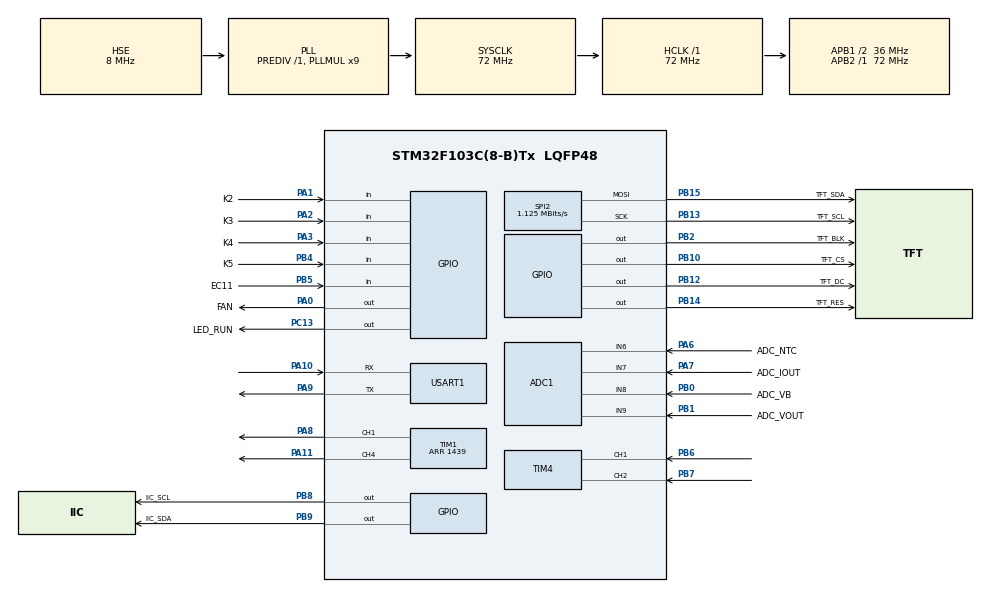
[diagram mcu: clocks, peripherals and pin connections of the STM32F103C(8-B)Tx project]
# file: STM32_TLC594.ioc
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ADC1.Channel-2\#ChannelRegularConversion=ADC_CHANNEL_6
ADC1.Channel-3\#ChannelRegularConversion=ADC_CHANNEL_7
ADC1.Channel-4\#ChannelRegularConversion=ADC_CHANNEL_8
ADC1.Channel-5\#ChannelRegularConversion=ADC_CHANNEL_9
ADC1.ContinuousConvMode=ENABLE
ADC1.EnableInjectedConversion=DISABLE
ADC1.EnableRegularConversion=ENABLE
ADC1.NbrOfConversion=4
ADC1.NbrOfConversionFlag=1
ADC1.Rank-2\#ChannelRegularConversion=1
ADC1.Rank-3\#ChannelRegularConversion=2
ADC1.Rank-4\#ChannelRegularConversion=3
ADC1.Rank-5\#ChannelRegularConversion=4
ADC1.SamplingTime-2\#ChannelRegularConversion=ADC_SAMPLETIME_13CYCLES_5
ADC1.SamplingTime-3\#ChannelRegularConversion=ADC_SAMPLETIME_13CYCLES_5
ADC1.SamplingTime-4\#ChannelRegularConversion=ADC_SAMPLETIME_13CYCLES_5
ADC1.SamplingTime-5\#ChannelRegularConversion=ADC_SAMPLETIME_13CYCLES_5
ADC1.master=1
Dma.ADC1.0.Direction=DMA_PERIPH_TO_MEMORY
Dma.ADC1.0.Instance=DMA1_Channel1
Dma.ADC1.0.MemDataAlignment=DMA_MDATAALIGN_HALFWORD
Dma.ADC1.0.MemInc=DMA_MINC_ENABLE
Dma.ADC1.0.Mode=DMA_CIRCULAR
Dma.ADC1.0.PeriphDataAlignment=DMA_PDATAALIGN_HALFWORD
Dma.ADC1.0.PeriphInc=DMA_PINC_DISABLE
Dma.ADC1.0.Priority=DMA_PRIORITY_HIGH
Dma.Request0=ADC1
Mcu.Family=STM32F1
Mcu.Name=STM32F103C(8-B)Tx
Mcu.Package=LQFP48
NVIC.DMA1_Channel1_IRQn=true\:0\:0\:false\:false\:true\:false\:true\:true
NVIC.PriorityGroup=NVIC_PRIORITYGROUP_4
NVIC.TIM2_IRQn=true\:0\:0\:false\:false\:true\:true\:true\:true
NVIC.TIM4_IRQn=true\:0\:0\:false\:false\:true\:true\:true\:true
NVIC.USART1_IRQn=true\:0\:0\:false\:false\:true\:true\:true\:true
PA0-WKUP.GPIO_Label=FAN
PA0-WKUP.PinState=GPIO_PIN_RESET
PA0-WKUP.Signal=GPIO_Output
PA1.GPIO_Label=K2
PA1.GPIO_PuPd=GPIO_PULLUP
PA1.Signal=GPIO_Input
PA10.Mode=Asynchronous
PA10.Signal=USART1_RX
PA11.Signal=S_TIM1_CH4
PA13.Mode=Serial_Wire
PA13.Signal=SYS_JTMS-SWDIO
PA14.Mode=Serial_Wire
PA14.Signal=SYS_JTCK-SWCLK
PA2.GPIO_Label=K3
PA2.GPIO_PuPd=GPIO_PULLUP
PA2.Signal=GPIO_Input
PA3.GPIO_Label=K4
PA3.GPIO_PuPd=GPIO_PULLUP
PA3.Signal=GPIO_Input
PA6.GPIO_Label=ADC_NTC
PA6.Signal=ADCx_IN6
PA7.GPIO_Label=ADC_IOUT
PA7.Signal=ADCx_IN7
PA8.Signal=S_TIM1_CH1
PA9.Mode=Asynchronous
PA9.Signal=USART1_TX
PB0.GPIO_Label=ADC_VB
PB0.Signal=ADCx_IN8
PB1.GPIO_Label=ADC_VOUT
PB1.Signal=ADCx_IN9
PB10.GPIO_Label=TFT_CS
PB10.PinState=GPIO_PIN_SET
PB10.Signal=GPIO_Output
PB12.GPIO_Label=TFT_DC
PB12.PinState=GPIO_PIN_SET
PB12.Signal=GPIO_Output
PB13.GPIO_Label=TFT_SCL
PB13.Mode=TX_Only_Simplex_Unidirect_Master
PB13.Signal=SPI2_SCK
PB14.GPIO_Label=TFT_RES
PB14.PinState=GPIO_PIN_SET
PB14.Signal=GPIO_Output
PB15.GPIO_Label=TFT_SDA
PB15.Mode=TX_Only_Simplex_Unidirect_Master
PB15.Signal=SPI2_MOSI
PB2.GPIO_Label=TFT_BLK
PB2.Signal=GPIO_Output
PB4.GPIO_Label=K5
PB4.GPIO_PuPd=GPIO_PULLUP
PB4.Signal=GPIO_Input
PB5.GPIO_Label=EC11
PB5.GPIO_PuPd=GPIO_PULLUP
PB5.Signal=GPIO_Input
PB6.GPIO_PuPd=GPIO_PULLUP
PB6.Signal=S_TIM4_CH1
PB7.GPIO_PuPd=GPIO_PULLUP
PB7.Signal=S_TIM4_CH2
PB8.GPIO_Label=IIC_SCL
PB8.GPIO_Speed=GPIO_SPEED_FREQ_HIGH
PB8.Signal=GPIO_Output
PB9.GPIO_Label=IIC_SDA
PB9.GPIO_Speed=GPIO_SPEED_FREQ_HIGH
PB9.Signal=GPIO_Output
PC13-TAMPER-RTC.GPIO_Label=LED_RUN
PC13-TAMPER-RTC.Signal=GPIO_Output
PD0-OSC_IN.Mode=HSE-External-Oscillator
PD0-OSC_IN.Signal=RCC_OSC_IN
PD1-OSC_OUT.Mode=HSE-External-Oscillator
PD1-OSC_OUT.Signal=RCC_OSC_OUT
ProjectManager.HeapSize=0x200
ProjectManager.StackSize=0x400
ProjectManager.TargetToolchain=CMake
RCC.ADCPresc=RCC_ADCPCLK2_DIV6
RCC.AHBFreq_Value=72000000
RCC.APB1CLKDivider=RCC_HCLK_DIV2
RCC.APB1Freq_Value=36000000
RCC.APB1TimFreq_Value=72000000
RCC.APB2Freq_Value=72000000
RCC.APB2TimFreq_Value=72000000
RCC.HCLKFreq_Value=72000000
RCC.PLLMUL=RCC_PLL_MUL9
RCC.PLLSourceVirtual=RCC_PLLSOURCE_HSE
RCC.SYSCLKFreq_VALUE=72000000
RCC.SYSCLKSource=RCC_SYSCLKSOURCE_PLLCLK
RCC.USBFreq_Value=72000000
SH.ADCx_IN6.0=ADC1_IN6,IN6
SH.ADCx_IN7.0=ADC1_IN7,IN7
SH.ADCx_IN8.0=ADC1_IN8,IN8
SH.ADCx_IN9.0=ADC1_IN9,IN9
SH.S_TIM1_CH1.0=TIM1_CH1,PWM Generation1 CH1
SH.S_TIM1_CH4.0=TIM1_CH4,PWM Generation4 CH4
SH.S_TIM4_CH1.0=TIM4_CH1,Encoder_Interface
SH.S_TIM4_CH2.0=TIM4_CH2,Encoder_Interface
SPI2.BaudRatePrescaler=SPI_BAUDRATEPRESCALER_32
SPI2.CLKPhase=SPI_PHASE_2EDGE
SPI2.CLKPolarity=SPI_POLARITY_HIGH
SPI2.CalculateBaudRate=1.125 MBits/s
SPI2.Direction=SPI_DIRECTION_2LINES
SPI2.Mode=SPI_MODE_MASTER
SPI2.VirtualType=VM_MASTER
TIM1.AutoReloadPreload=TIM_AUTORELOAD_PRELOAD_ENABLE
TIM1.Channel-PWM\ Generation1\ CH1=TIM_CHANNEL_1
TIM1.Channel-PWM\ Generation4\ CH4=TIM_CHANNEL_4
TIM1.Period=1439
TIM1.Pulse-PWM\ Generation1\ CH1=720
TIM1.Pulse-PWM\ Generation4\ CH4=720
TIM2.AutoReloadPreload=TIM_AUTORELOAD_PRELOAD_ENABLE
TIM2.Period=4999
TIM2.Prescaler=71
TIM3.Period=89
TIM4.IC1Filter=6
TIM4.IC2Filter=6
USART1.VirtualMode=VM_ASYNC
VP_TIM2_VS_ClockSourceINT.Mode=Internal
VP_TIM3_VS_ClockSourceINT.Mode=Internal
board=custom

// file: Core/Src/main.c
/* USER CODE BEGIN Header */
/**
  ******************************************************************************
  * @file           : main.c
  * @brief          : Main program body
  ******************************************************************************
  * @attention
  *
  * Copyright (c) 2025 STMicroelectronics.
  * All rights reserved.
  *
  * This software is licensed under terms that can be found in the LICENSE file
  * in the root directory of this software component.
  * If no LICENSE file comes with this software, it is provided AS-IS.
  *
  ******************************************************************************
  */
/* USER CODE END Header */
#include "main.h"
#include "adc.h"
#include "dma.h"
#include "spi.h"
#include "tim.h"
#include "usart.h"
#include "gpio.h"

/* USER CODE BEGIN Includes */
#include "MyApplication.h"

/* USER CODE END Includes */

void SystemClock_Config(void);

int main(void)
{

  /* USER CODE BEGIN 1 */
  //uint8_t Key_num;
  Function_SET.OutPutState = CV_State;
  /* USER CODE END 1 */

  /* MCU Configuration--------------------------------------------------------*/

  /* Reset of all peripherals, Initializes the Flash interface and the Systick. */
  HAL_Init();

  /* Configure the system clock */
  SystemClock_Config();

  /* Initialize all configured peripherals */
  MX_GPIO_Init();
  MX_DMA_Init();
  MX_ADC1_Init();
  MX_TIM1_Init();
  MX_TIM2_Init();
  MX_TIM3_Init();
  MX_TIM4_Init();
  MX_USART1_UART_Init();
  MX_SPI2_Init();
  /* USER CODE BEGIN 2 */
  MyInit.Peripheral_Set();

  /* USER CODE END 2 */

  /* Infinite loop */
  while (1)
  {

    /* USER CODE BEGIN 3 */
    System.Run();
  }
  /* USER CODE END 3 */
}

void SystemClock_Config(void)
{
  RCC_OscInitTypeDef RCC_OscInitStruct = {0};
  RCC_ClkInitTypeDef RCC_ClkInitStruct = {0};
  RCC_PeriphCLKInitTypeDef PeriphClkInit = {0};

  /** Initializes the RCC Oscillators according to the specified parameters
  * in the RCC_OscInitTypeDef structure.
  */
  RCC_OscInitStruct.OscillatorType = RCC_OSCILLATORTYPE_HSE;
  RCC_OscInitStruct.HSEState = RCC_HSE_ON;
  RCC_OscInitStruct.HSEPredivValue = RCC_HSE_PREDIV_DIV1;
  RCC_OscInitStruct.HSIState = RCC_HSI_ON;
  RCC_OscInitStruct.PLL.PLLState = RCC_PLL_ON;
  RCC_OscInitStruct.PLL.PLLSource = RCC_PLLSOURCE_HSE;
  RCC_OscInitStruct.PLL.PLLMUL = RCC_PLL_MUL9;
  if (HAL_RCC_OscConfig(&RCC_OscInitStruct) != HAL_OK)
  {
    Error_Handler();
  }

  /** Initializes the CPU, AHB and APB buses clocks
  */
  RCC_ClkInitStruct.ClockType = RCC_CLOCKTYPE_HCLK|RCC_CLOCKTYPE_SYSCLK
                              |RCC_CLOCKTYPE_PCLK1|RCC_CLOCKTYPE_PCLK2;
  RCC_ClkInitStruct.SYSCLKSource = RCC_SYSCLKSOURCE_PLLCLK;
  RCC_ClkInitStruct.AHBCLKDivider = RCC_SYSCLK_DIV1;
  RCC_ClkInitStruct.APB1CLKDivider = RCC_HCLK_DIV2;
  RCC_ClkInitStruct.APB2CLKDivider = RCC_HCLK_DIV1;

  if (HAL_RCC_ClockConfig(&RCC_ClkInitStruct, FLASH_LATENCY_2) != HAL_OK)
  {
    Error_Handler();
  }
  PeriphClkInit.PeriphClockSelection = RCC_PERIPHCLK_ADC;
  PeriphClkInit.AdcClockSelection = RCC_ADCPCLK2_DIV6;
  if (HAL_RCCEx_PeriphCLKConfig(&PeriphClkInit) != HAL_OK)
  {
    Error_Handler();
  }
}

void Error_Handler(void)
{
  __disable_irq();
  while (1)
  {
  }
}
